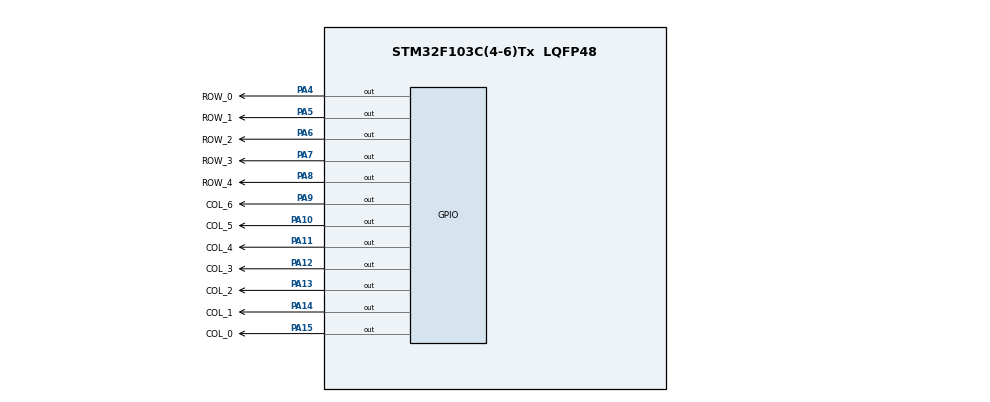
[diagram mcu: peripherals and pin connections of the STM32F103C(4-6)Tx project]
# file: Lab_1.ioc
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Mcu.Family=STM32F1
Mcu.Name=STM32F103C(4-6)Tx
Mcu.Package=LQFP48
NVIC.PriorityGroup=NVIC_PRIORITYGROUP_4
PA10.GPIO_Label=COL_5
PA10.Signal=GPIO_Output
PA11.GPIO_Label=COL_4
PA11.Signal=GPIO_Output
PA12.GPIO_Label=COL_3
PA12.Signal=GPIO_Output
PA13.GPIO_Label=COL_2
PA13.Signal=GPIO_Output
PA14.GPIO_Label=COL_1
PA14.Signal=GPIO_Output
PA15.GPIO_Label=COL_0
PA15.Signal=GPIO_Output
PA4.GPIO_Label=ROW_0
PA4.Signal=GPIO_Output
PA5.GPIO_Label=ROW_1
PA5.Signal=GPIO_Output
PA6.GPIO_Label=ROW_2
PA6.Signal=GPIO_Output
PA7.GPIO_Label=ROW_3
PA7.Signal=GPIO_Output
PA8.GPIO_Label=ROW_4
PA8.Signal=GPIO_Output
PA9.GPIO_Label=COL_6
PA9.Signal=GPIO_Output
PD0-OSC_IN.Mode=HSE-External-Oscillator
PD0-OSC_IN.Signal=RCC_OSC_IN
PD1-OSC_OUT.Mode=HSE-External-Oscillator
PD1-OSC_OUT.Signal=RCC_OSC_OUT
ProjectManager.HeapSize=0x200
ProjectManager.StackSize=0x400
ProjectManager.TargetToolchain=STM32CubeIDE
RCC.APB1Freq_Value=8000000
RCC.APB2Freq_Value=8000000
RCC.SYSCLKSource=RCC_SYSCLKSOURCE_HSE
VP_SYS_VS_ND.Mode=No_Debug
board=custom

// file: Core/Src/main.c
/* USER CODE BEGIN Header */
/**
  ******************************************************************************
  * @file           : main.c
  * @brief          : Main program body
  ******************************************************************************
  * @attention
  *
  * <h2><center>&copy; Copyright (c) 2021 STMicroelectronics.
  * All rights reserved.</center></h2>
  *
  * This software component is licensed by ST under BSD 3-Clause license,
  * the "License"; You may not use this file except in compliance with the
  * License. You may obtain a copy of the License at:
  *                        opensource.org/licenses/BSD-3-Clause
  *
  ******************************************************************************
  */
/* USER CODE END Header */
#include "main.h"

void SystemClock_Config(void);
static void MX_GPIO_Init(void);

int main(void)
{

  /* MCU Configuration--------------------------------------------------------*/

  /* Reset of all peripherals, Initializes the Flash interface and the Systick. */
  HAL_Init();

  /* Configure the system clock */
  SystemClock_Config();

  /* Initialize all configured peripherals */
  MX_GPIO_Init();

  /* Infinite loop */
  /* USER CODE BEGIN WHILE */

  int second = 0;
  int minute = 0;
  int hour = 0;
//  int counter = 0;
  while (1)
  {
    /* USER CODE END WHILE */
//	  if (counter==1){
//		  second++;
//		  counter = 0;
//	  }
//	  else {
//		  counter++;
//	  }
	  second++;
	  if (second >= MAX_MINUTE){
		  second=0;
		  minute++;
	  }
	  if (minute>=MAX_MINUTE){
		  minute=0;
		  hour++;
	  }
	  if (hour >= MAX_HOUR){
		  hour = 0;
	  }
	  displayClock(second, minute, hour);
  }
}

void SystemClock_Config(void)
{
  RCC_OscInitTypeDef RCC_OscInitStruct = {0};
  RCC_ClkInitTypeDef RCC_ClkInitStruct = {0};

  /** Initializes the RCC Oscillators according to the specified parameters
  * in the RCC_OscInitTypeDef structure.
  */
  RCC_OscInitStruct.OscillatorType = RCC_OSCILLATORTYPE_HSE;
  RCC_OscInitStruct.HSEState = RCC_HSE_ON;
  RCC_OscInitStruct.PLL.PLLState = RCC_PLL_NONE;
  if (HAL_RCC_OscConfig(&RCC_OscInitStruct) != HAL_OK)
  {
    Error_Handler();
  }
  /** Initializes the CPU, AHB and APB buses clocks
  */
  RCC_ClkInitStruct.ClockType = RCC_CLOCKTYPE_HCLK|RCC_CLOCKTYPE_SYSCLK
                              |RCC_CLOCKTYPE_PCLK1|RCC_CLOCKTYPE_PCLK2;
  RCC_ClkInitStruct.SYSCLKSource = RCC_SYSCLKSOURCE_HSE;
  RCC_ClkInitStruct.AHBCLKDivider = RCC_SYSCLK_DIV1;
  RCC_ClkInitStruct.APB1CLKDivider = RCC_HCLK_DIV1;
  RCC_ClkInitStruct.APB2CLKDivider = RCC_HCLK_DIV1;

  if (HAL_RCC_ClockConfig(&RCC_ClkInitStruct, FLASH_LATENCY_0) != HAL_OK)
  {
    Error_Handler();
  }
}

static void MX_GPIO_Init(void)
{
  GPIO_InitTypeDef GPIO_InitStruct = {0};

  /* GPIO Ports Clock Enable */
  __HAL_RCC_GPIOD_CLK_ENABLE();
  __HAL_RCC_GPIOA_CLK_ENABLE();

  /*Configure GPIO pin Output Level */
  HAL_GPIO_WritePin(GPIOA, ROW_0_Pin|ROW_1_Pin|ROW_2_Pin|ROW_3_Pin
                          |ROW_4_Pin|COL_6_Pin|COL_5_Pin|COL_4_Pin
                          |COL_3_Pin|COL_2_Pin|COL_1_Pin|COL_0_Pin, GPIO_PIN_RESET);

  /*Configure GPIO pins : ROW_0_Pin ROW_1_Pin ROW_2_Pin ROW_3_Pin
                           ROW_4_Pin COL_6_Pin COL_5_Pin COL_4_Pin
                           COL_3_Pin COL_2_Pin COL_1_Pin COL_0_Pin */
  GPIO_InitStruct.Pin = ROW_0_Pin|ROW_1_Pin|ROW_2_Pin|ROW_3_Pin
                          |ROW_4_Pin|COL_6_Pin|COL_5_Pin|COL_4_Pin
                          |COL_3_Pin|COL_2_Pin|COL_1_Pin|COL_0_Pin;
  GPIO_InitStruct.Mode = GPIO_MODE_OUTPUT_PP;
  GPIO_InitStruct.Pull = GPIO_NOPULL;
  GPIO_InitStruct.Speed = GPIO_SPEED_FREQ_LOW;
  HAL_GPIO_Init(GPIOA, &GPIO_InitStruct);

}

void Error_Handler(void)
{
  __disable_irq();
  while (1)
  {
  }
}

/************************ (C) COPYRIGHT STMicroelectronics *****END OF FILE****/
